# AVR16DD20 register map
Vendor: Atmel; File version: 1.0
CPU: other r0p0, little endian, no MPU, no FPU, 4 interrupt priority bits
Registers are 8-bit, read-write, reset 0x0 unless marked. A register's access mark holds for its fields unless they carry their own. Offsets are from the block's base; [hi:lo] are bit positions; {n}, {i} and the like mark numbered series; 'fields as' and 'values as' point back to an identical list.

## CCL — Configurable Custom Logic
Base 0x008001C0
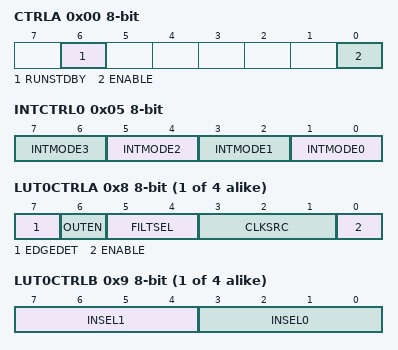
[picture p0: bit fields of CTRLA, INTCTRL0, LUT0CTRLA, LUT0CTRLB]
0x00 CTRLA — Control Register A
  [6] RUNSTDBY — Run in Standby
  [0] ENABLE
0x01 SEQCTRL0 — Sequential Control 0
  [3:0] SEQSEL — Sequential Selection
    0=DISABLE (Sequential logic disabled); 1=DFF (D FlipFlop); 2=JK (JK FlipFlop); 3=LATCH (D Latch); 4=RS (RS Latch)
0x02 SEQCTRL1 — Sequential Control 1
  fields as SEQCTRL0
0x05 INTCTRL0 — Interrupt Control 0
  [all] fields
    0=INTDISABLE (Interrupt disabled); 1=RISING (Sense rising edge); 2=FALLING (Sense falling edge); 3=BOTH (Sense both edges)
  [2n+1:2n] INTMODE{n} (n=0..3) — Interrupt Mode for LUT{n}
0x07 INTFLAGS — Interrupt Flags
  [3:0] INT — Interrupt Flag
{0x8+4i} LUT{i}CTRLA (i=0..3) — LUT {i} Control A
  [7] EDGEDET — Edge Detection Enable
    0=DIS (Edge detector is disabled); 1=EN (Edge detector is enabled)
  [6] OUTEN — Output Enable
  [5:4] FILTSEL — Filter Selection
    0=DISABLE (Filter disabled); 1=SYNCH (Synchronizer enabled); 2=FILTER (Filter enabled)
  [3:1] CLKSRC — Clock Source Selection
    0=CLKPER (Peripheral Clock); 1=IN2 (Selection by INSEL2); 4=OSCHF (Internal High-Frequency Oscillator); 5=OSC32K (32.768 kHz oscillator); 6=OSC1K (32.768 kHz oscillator divided by 32)
  [0] ENABLE — LUT Enable
{0x9+4i} LUT{i}CTRLB (i=0..3) — LUT {i} Control B
  [7:4] INSEL1 — LUT Input 1 Source Selection
    0=MASK (Masked input); 1=FEEDBACK (Feedback input source); 2=LINK (Linked LUT input source); 3=EVENTA (Event input source A); 4=EVENTB (Event input source B); 5=IN1 (IO pin LUTn-IN1 input source); 6=AC0 (AC0 OUT input source); 7=ZCD3 (ZCD3 OUT input source); 8=USART1 (USART1 TXD input source); 9=SPI0 (SPI0 MOSI input source); 10=TCA0 (TCA0 WO1 input source); 11=TCB1 (TCB1 WO input source); 12=TCD0 (TCD0 WOB input source)
  [3:0] INSEL0 — LUT Input 0 Source Selection
    0=MASK (Masked input); 1=FEEDBACK (Feedback input source); 2=LINK (Linked LUT input source); 3=EVENTA (Event input source A); 4=EVENTB (Event input source B); 5=IN0 (IO pin LUTn-IN0 input source); 6=AC0 (AC0 OUT input source); 7=ZCD3 (ZCD3 OUT input source); 8=USART0 (USART0 TXD input source); 9=SPI0 (SPI0 MOSI input source); 10=TCA0 (TCA0 WO0 input source); 11=TCB0 (TCB0 WO input source); 12=TCD0 (TCD0 WOA input source)
{0xA+4i} LUT{i}CTRLC (i=0..3) — LUT {i} Control C
  [3:0] INSEL2 — LUT Input 2 Source Selection
    0=MASK (Masked input); 1=FEEDBACK (Feedback input source); 2=LINK (Linked LUT input source); 3=EVENTA (Event input source A); 4=EVENTB (Event input source B); 5=IN2 (IO pin LUTn-IN2 input source); 6=AC0 (AC0 OUT input source); 7=ZCD3 (ZCD3 OUT input source); 8=USART1 (USART1 TXD input source); 9=SPI0 (SPI0 SCK input source); 10=TCA0 (TCA0 WO2 input source); 11=TCB2 (TCB2 WO input source); 12=TCD0 (TCD0 WOC input source)
{0xB+4i} TRUTH{i} (i=0..3)
  [7:0] TRUTH — Truth Table

## CLKCTRL — Clock controller
Base 0x00800060
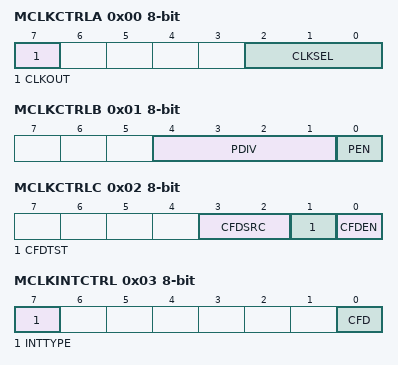
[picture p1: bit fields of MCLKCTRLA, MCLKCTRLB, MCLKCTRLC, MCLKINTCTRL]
0x00 MCLKCTRLA — MCLK Control A
  [7] CLKOUT — System clock out
  [2:0] CLKSEL — Clock select
    0=OSCHF (Internal high-frequency oscillator); 1=OSC32K (Internal 32.768 kHz oscillator); 2=XOSC32K (32.768 kHz crystal oscillator); 3=EXTCLK (External clock)
0x01 MCLKCTRLB — MCLK Control B
  [4:1] PDIV — Prescaler division
    0=2X; 1=4X; 2=8X; 3=16X; 4=32X; 5=64X; 8=6X; 9=10X; 10=12X; 11=24X; 12=48X
  [0] PEN — Prescaler enable
0x02 MCLKCTRLC — MCLK Control C
  [3:2] CFDSRC — Clock Failure Detect Source
    0=CLKMAIN (Main Clock); 1=XOSCHF; 2=XOSC32K
  [1] CFDTST wo — Clock Failure Detect Test
  [0] CFDEN — Clock Failure Detect Enable
0x03 MCLKINTCTRL — MCLK Interrupt Control
  [7] INTTYPE — Interrupt type
    0=INT (Regular Interrupt); 1=NMI
  [0] CFD — Clock Failure Detect Interrupt Enable
0x04 MCLKINTFLAGS — MCLK Interrupt Flags
  [0] CFD — Clock Failure Detect Interrupt Flag
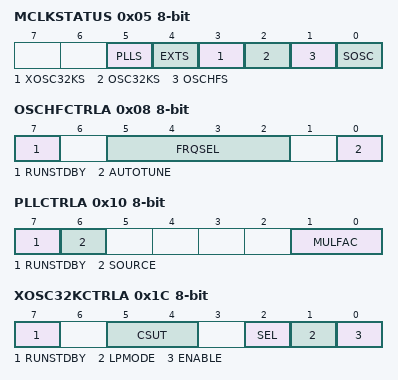
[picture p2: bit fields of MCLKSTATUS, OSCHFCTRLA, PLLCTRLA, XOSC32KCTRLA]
0x05 MCLKSTATUS
  [5] PLLS — PLL oscillator status
  [4] EXTS — External Clock status
  [3] XOSC32KS — 32.768 kHz Crystal Oscillator status
  [2] OSC32KS — 32KHz oscillator status
  [1] OSCHFS — High frequency oscillator status
  [0] SOSC — System Oscillator changing
0x08 OSCHFCTRLA — OSCHF Control A
  [7] RUNSTDBY — Run standby
  [5:2] FRQSEL — Frequency select
    0=1M (1 MHz system clock); 1=2M (2 MHz system clock); 2=3M (3 MHz system clock); 3=4M (4 MHz system clock (default)); 5=8M (8 MHz system clock); 6=12M (12 MHz system clock); 7=16M (16 MHz system clock); 8=20M (20 MHz system clock); 9=24M (24 MHz system clock)
  [0] AUTOTUNE
0x09 OSCHFTUNE
  [7:0] TUNE
0x10 PLLCTRLA — PLL Control A
  [7] RUNSTDBY — Run standby
  [6] SOURCE
    0=OSCHF (High frequency internal oscillator as PLL source); 1=XOSCHF (High frequency external clock or external high frequency oscillator as PLL source)
  [1:0] MULFAC — Multiplication factor
    0=DISABLE (PLL is disabled); 1=2x (2 x multiplication factor); 2=3x (3 x multiplication factor)
0x18 OSC32KCTRLA — OSC32K Control A
  [7] RUNSTDBY — Run standby
0x1C XOSC32KCTRLA — XOSC32K Control A
  [7] RUNSTDBY — Run standby
  [5:4] CSUT — Crystal startup time
    0=1K (1k cycles); 1=16K (16k cycles); 2=32K (32k cycles); 3=64K (64k cycles)
  [2] SEL — Select
  [1] LPMODE — Low power mode
  [0] ENABLE
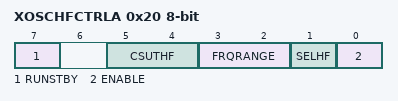
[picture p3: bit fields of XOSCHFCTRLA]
0x20 XOSCHFCTRLA — XOSC HF Control A
  [7] RUNSTBY — Run Standby
  [5:4] CSUTHF — Start-up Time Select
    0=256 XOSCHF cycles; 1=1K (1K XOSCHF cycles); 2=4K (4K XOSCHF cycles)
  [3:2] FRQRANGE — Frequency Range
    0=8M (Max 8 MHz XTAL Frequency); 1=16M (Max 16 MHz XTAL Frequency); 2=24M (Max 24 MHz XTAL Frequency); 3=32M (Max 32 MHz XTAL Frequency)
  [1] SELHF — External Source Select
    0=XTAL (External Crystal); 1=EXTCLOCK (External clock on XTALHF1 pin)
  [0] ENABLE
